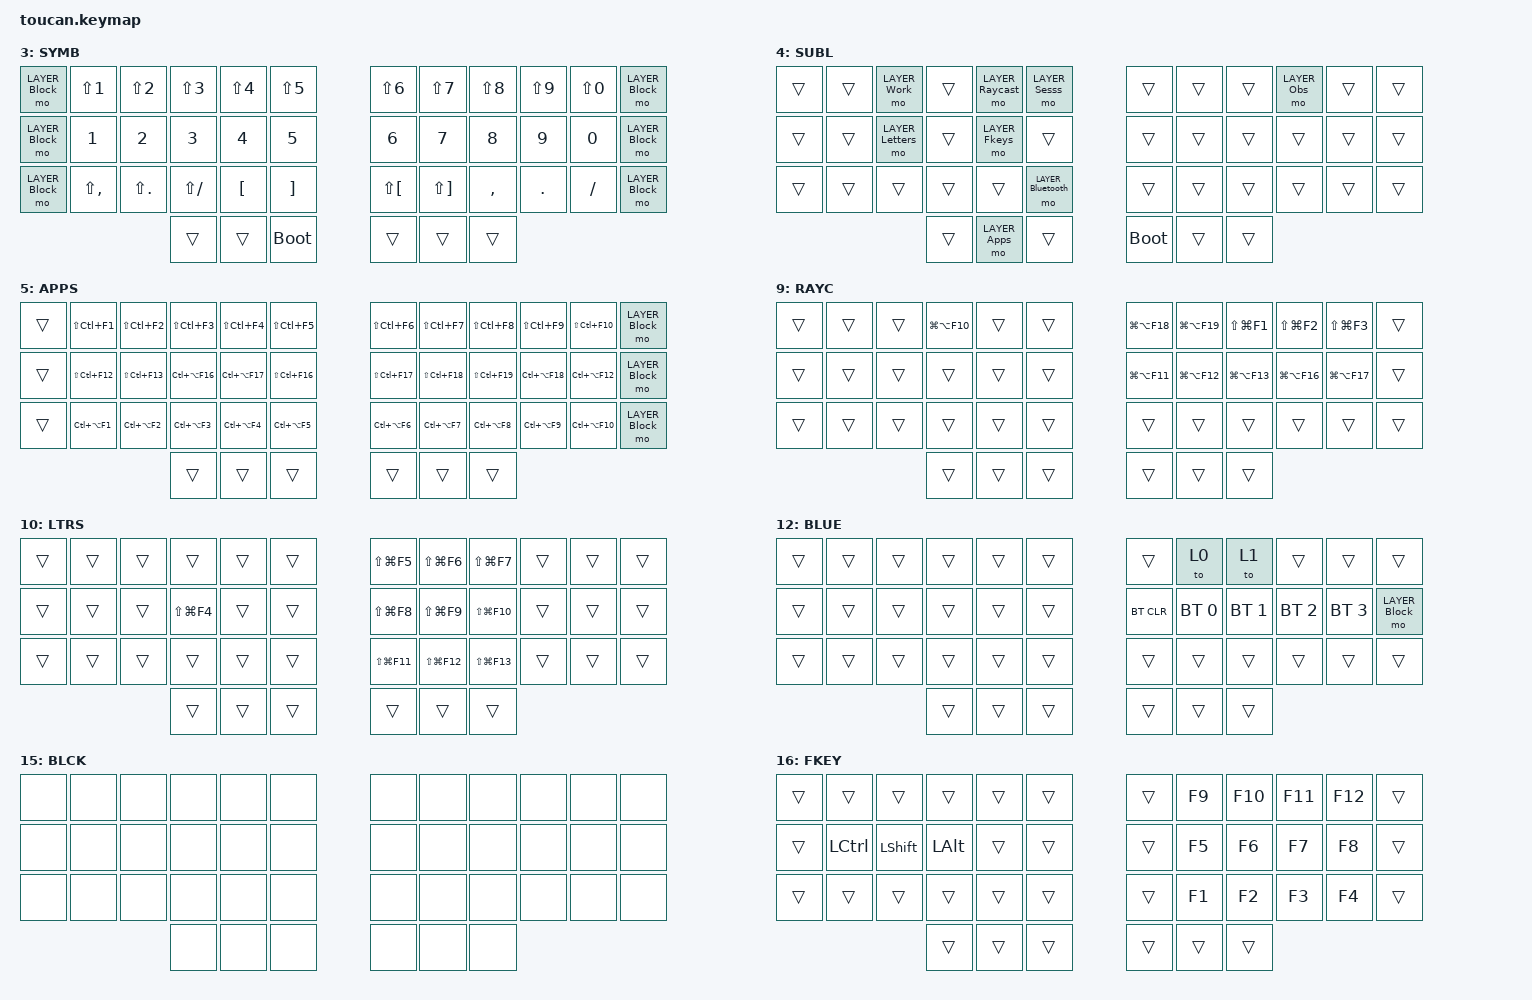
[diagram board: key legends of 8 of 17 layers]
#include <behaviors.dtsi>
#include <dt-bindings/zmk/keys.h>
#include <dt-bindings/zmk/bt.h>
#include <dt-bindings/zmk/outputs.h>

// Adding pointing.h to be able to right and middle click
// https://zmk.dev/docs/keymaps/behaviors/mouse-emulation
#include <dt-bindings/zmk/pointing.h>

#define LAYER_macOS 0
#define LAYER_Windows 1
#define LAYER_Nav 2
#define LAYER_Symb 3
#define LAYER_Subl 4
#define LAYER_Apps 5
#define LAYER_Sesss 6
#define LAYER_Systm 7
#define LAYER_Yabai 8
#define LAYER_Raycast 9
#define LAYER_Letters 10
#define LAYER_Obs 11
#define LAYER_Bluetooth 12
#define LAYER_Obspos 13
#define LAYER_Work 14
#define LAYER_Block 15
#define LAYER_Fkeys 16

/ {
    behaviors {
        // Home-row mods: a key only becomes the modifier once it has been held for tapping-term-ms.
        hrm_l: hrm_l {
            compatible = "zmk,behavior-hold-tap";
            #binding-cells = <2>;
            tapping-term-ms = <300>;
            bindings = <&kp>, <&kp>;
            flavor = "tap-preferred";
            quick-tap-ms = <300>;
        };

        hrm_r: hrm_r {
            compatible = "zmk,behavior-hold-tap";
            #binding-cells = <2>;
            tapping-term-ms = <300>;
            bindings = <&kp>, <&kp>;
            flavor = "tap-preferred";
            quick-tap-ms = <300>;
        };

        // Windows home-row mods, both hands.
        hrm_w: hrm_w {
            compatible = "zmk,behavior-hold-tap";
            #binding-cells = <2>;
            tapping-term-ms = <200>;
            bindings = <&kp>, <&kp>;
            flavor = "tap-preferred";
            quick-tap-ms = <200>;
            retro-tap;
        };

        my_mt: my_mt {
            compatible = "zmk,behavior-hold-tap";
            #binding-cells = <2>;
            flavor = "tap-preferred";
            tapping-term-ms = <300>;
            bindings = <&kp>, <&kp>;
        };

        my_lt: my_lt {
            compatible = "zmk,behavior-hold-tap";
            #binding-cells = <2>;
            flavor = "tap-preferred";
            tapping-term-ms = <300>;
            bindings = <&mo>, <&kp>;
        };

        my_mtw: my_mtw {
            compatible = "zmk,behavior-hold-tap";
            #binding-cells = <2>;
            flavor = "tap-preferred";
            tapping-term-ms = <200>;
            bindings = <&kp>, <&kp>;
        };

        h_third_app: h_third_app {
            compatible = "zmk,behavior-hold-tap";
            #binding-cells = <2>;
            flavor = "tap-preferred";
            tapping-term-ms = <300>;
            bindings = <&third_app>, <&kp>;
        };

    };

    macros {
        third_app: third_app {
            compatible = "zmk,behavior-macro";
            #binding-cells = <0>;
            wait-ms = <40>;
            tap-ms = <40>;
            bindings
                = <&macro_press &kp LGUI>
                , <&macro_tap &kp TAB &kp TAB>
                , <&macro_release &kp LGUI>
                ;
        };

    };

#define TRANSITION_COMBO_TIMEOUT_MS 35
#define TRANSITION_COMBO_PRIOR_IDLE_MS 125

    combos {
        compatible = "zmk,combos";

        combo_mac_tab_ret {
            // Both keys must be pressed within this window.
            timeout-ms = <TRANSITION_COMBO_TIMEOUT_MS>;
            // Avoids accidental combos during fast typing/rolls.
            require-prior-idle-ms = <TRANSITION_COMBO_PRIOR_IDLE_MS>;
            // Keeps hold-tap combos held until both combo keys are released.
            slow-release;
            // Physical positions for W and E.
            key-positions = <2 3>;
            // Only active on macOS, so W+E can mean something else on other layers.
            layers = <LAYER_macOS>;
            // Reuses my existing hold-tap: hold sends RET, tap sends TAB.
            bindings = <&my_mt RET TAB>;
        };

        combo_win_tab_ret {
            timeout-ms = <TRANSITION_COMBO_TIMEOUT_MS>;
            require-prior-idle-ms = <TRANSITION_COMBO_PRIOR_IDLE_MS>;
            slow-release;
            key-positions = <2 3>;
            layers = <LAYER_Windows>;
            bindings = <&my_mtw RET TAB>;
        };

        combo_sd_esc {
            timeout-ms = <TRANSITION_COMBO_TIMEOUT_MS>;
            require-prior-idle-ms = <TRANSITION_COMBO_PRIOR_IDLE_MS>;
            slow-release;
            key-positions = <14 15>;
            layers = <LAYER_macOS LAYER_Windows>;
            bindings = <&kp ESC>;
        };

        combo_df_space {
            timeout-ms = <TRANSITION_COMBO_TIMEOUT_MS>;
            require-prior-idle-ms = <TRANSITION_COMBO_PRIOR_IDLE_MS>;
            key-positions = <15 16>;
            layers = <LAYER_macOS LAYER_Windows>;
            bindings = <&kp SPACE>;
        };

        combo_er_speech {
            timeout-ms = <TRANSITION_COMBO_TIMEOUT_MS>;
            require-prior-idle-ms = <TRANSITION_COMBO_PRIOR_IDLE_MS>;
            key-positions = <3 4>;
            layers = <LAYER_macOS LAYER_Windows>;
            bindings = <&kp LG(LC(LA(LS(S))))>;
        };

        combo_bslh {
            timeout-ms = <TRANSITION_COMBO_TIMEOUT_MS>;
            require-prior-idle-ms = <TRANSITION_COMBO_PRIOR_IDLE_MS>;
            key-positions = <8 9>;
            layers = <LAYER_macOS LAYER_Windows>;
            bindings = <&kp BSLH>;
        };

        combo_sqt {
            timeout-ms = <TRANSITION_COMBO_TIMEOUT_MS>;
            require-prior-idle-ms = <TRANSITION_COMBO_PRIOR_IDLE_MS>;
            key-positions = <20 21>;
            layers = <LAYER_macOS LAYER_Windows>;
            bindings = <&kp SQT>;
        };

        combo_sym_under {
            timeout-ms = <TRANSITION_COMBO_TIMEOUT_MS>;
            require-prior-idle-ms = <TRANSITION_COMBO_PRIOR_IDLE_MS>;
            key-positions = <2 3>;
            layers = <LAYER_Symb>;
            bindings = <&kp LS(MINUS)>;
        };

        combo_sym_tilde {
            timeout-ms = <TRANSITION_COMBO_TIMEOUT_MS>;
            require-prior-idle-ms = <TRANSITION_COMBO_PRIOR_IDLE_MS>;
            key-positions = <14 15>;
            layers = <LAYER_Symb>;
            bindings = <&kp LS(GRAVE)>;
        };

        combo_sym_plus {
            timeout-ms = <TRANSITION_COMBO_TIMEOUT_MS>;
            require-prior-idle-ms = <TRANSITION_COMBO_PRIOR_IDLE_MS>;
            key-positions = <26 27>;
            layers = <LAYER_Symb>;
            bindings = <&kp LS(EQUAL)>;
        };

        combo_sym_minus {
            timeout-ms = <TRANSITION_COMBO_TIMEOUT_MS>;
            require-prior-idle-ms = <TRANSITION_COMBO_PRIOR_IDLE_MS>;
            key-positions = <8 9>;
            layers = <LAYER_Symb>;
            bindings = <&kp MINUS>;
        };

        combo_sym_grave {
            timeout-ms = <TRANSITION_COMBO_TIMEOUT_MS>;
            require-prior-idle-ms = <TRANSITION_COMBO_PRIOR_IDLE_MS>;
            key-positions = <20 21>;
            layers = <LAYER_Symb>;
            bindings = <&kp GRAVE>;
        };

        combo_sym_equal {
            timeout-ms = <TRANSITION_COMBO_TIMEOUT_MS>;
            require-prior-idle-ms = <TRANSITION_COMBO_PRIOR_IDLE_MS>;
            key-positions = <32 33>;
            layers = <LAYER_Symb>;
            bindings = <&kp EQUAL>;
        };

        combo_apps_r_top {
            timeout-ms = <TRANSITION_COMBO_TIMEOUT_MS>;
            require-prior-idle-ms = <TRANSITION_COMBO_PRIOR_IDLE_MS>;
            key-positions = <8 9>;
            layers = <LAYER_Apps>;
            bindings = <&kp LS(LC(F11))>;
        };

        combo_apps_r_home {
            timeout-ms = <TRANSITION_COMBO_TIMEOUT_MS>;
            require-prior-idle-ms = <TRANSITION_COMBO_PRIOR_IDLE_MS>;
            key-positions = <20 21>;
            layers = <LAYER_Apps>;
            bindings = <&kp LC(LA(F13))>;
        };

        combo_apps_r_bottom {
            timeout-ms = <TRANSITION_COMBO_TIMEOUT_MS>;
            require-prior-idle-ms = <TRANSITION_COMBO_PRIOR_IDLE_MS>;
            key-positions = <32 33>;
            layers = <LAYER_Apps>;
            bindings = <&kp LC(LA(F11))>;
        };

    };
};

/ {

    keymap {
        compatible = "zmk,keymap";

        layer_macOS {
            display-name = "mac";
            bindings = <
//    ┌──────────────────┬────────────────────┬────────────────────────┬──────────────────┬──────────────────────────┬─────────────────────────┐                ┌─────────────────────┬─────────────────────────┬───────────────┬────────────────────────────────────┬───────────────┬──────────────────┐
//    │ mo laltYER_Block │  &my_mt lctl(Z) Q  │ &my_lt laltYER_Systm W │ &my_mt lalt(E) E │ &my_mt lctl(lgui(f19)) R │ &my_mt lgui(lalt(f1)) T │                │          Y          │    &my_mt lgui(Z) U     │       I       │ &my_mt lgui(lctl(lalt(lsft(Z)))) O │       P       │ mo laltYER_Block │
//    ├──────────────────┼────────────────────┼────────────────────────┼──────────────────┼──────────────────────────┼─────────────────────────┤                ├─────────────────────┼─────────────────────────┼───────────────┼────────────────────────────────────┼───────────────┼──────────────────┤
//    │ mo laltYER_Block │   &hrm_l lgui A    │     &hrm_l lsft S      │  &hrm_l lalt D   │      &hrm_l lctl F       │  &my_lt laltYER_Nav G   │                │  &h_third_app 0 H   │      &hrm_r rctl J      │ &hrm_r ralt K │           &hrm_r rsft L            │ &hrm_r rgui ; │ mo laltYER_Block │
//    ├──────────────────┼────────────────────┼────────────────────────┼──────────────────┼──────────────────────────┼─────────────────────────┤                ├─────────────────────┼─────────────────────────┼───────────────┼────────────────────────────────────┼───────────────┼──────────────────┤
//    │ mo laltYER_Block │ &my_mt lgui(tab) Z │    &my_mt lgui(`) X    │ &my_mt lgui(C) C │     &my_mt lgui(V) V     │ &my_mt lgui(lalt(f8)) B │                │  &my_mt lalt(N) N   │ &my_mt lgui(lalt(f9)) M │       ,       │ &my_mt lgui(lctl(lalt(lsft(6)))) . │       /       │ mo laltYER_Block │
//    └──────────────────┴────────────────────┴────────────────────────┴──────────────────┼──────────────────────────┼─────────────────────────┼──────┐   ┌─────┼─────────────────────┼─────────────────────────┼───────────────┴────────────────────────────────────┴───────────────┴──────────────────┘
//                                                                                        │                          │  lt laltYER_Symb bspc   │ lsft │   │ spc │ lt laltYER_Subl ent │                         │
//                                                                                        └──────────────────────────┴─────────────────────────┴──────┘   └─────┴─────────────────────┴─────────────────────────┘
  &mo LAYER_Block   &my_mt LC(Z) Q     &my_lt LAYER_Systm W   &my_mt LA(E) E   &my_mt LC(LG(F19)) R   &my_mt LG(LA(F1)) T                               &kp Y                &my_mt LG(Z) U        &kp I           &my_mt LG(LC(LA(LS(Z)))) O     &kp P              &mo LAYER_Block
  &mo LAYER_Block   &hrm_l LGUI A      &hrm_l LSHFT S         &hrm_l LALT D    &hrm_l LCTRL F         &my_lt LAYER_Nav G                                &h_third_app 0 H     &hrm_r RCTRL J        &hrm_r RALT K   &hrm_r RSHFT L                 &hrm_r RGUI SEMI   &mo LAYER_Block
  &mo LAYER_Block   &my_mt LG(TAB) Z   &my_mt LG(GRAVE) X     &my_mt LG(C) C   &my_mt LG(V) V         &my_mt LG(LA(F8)) B                               &my_mt LA(N) N       &my_mt LG(LA(F9)) M   &kp COMMA       &my_mt LG(LC(LA(LS(6)))) DOT   &kp FSLH           &mo LAYER_Block
                                                                               &none                  &lt LAYER_Symb BSPC   &kp LSHFT       &kp SPACE   &lt LAYER_Subl RET   &none
            >;
        };

        layer_Windows {
            display-name = "WNDS";
            bindings = <
//    ┌──────────────────┬────────────────────────────────┬────────────────────────────────┬───────────────────┬───────────────────────────┬──────────────────────────┐                ┌─────────────────────┬──────────────────┬───────────────┬───────────────┬───────────────┬──────────────────┐
//    │ mo laltYER_Block │               Q                │       lt laltYER_Systm W       │         E         │ &my_mtw lctl(lgui(f19)) R │ &my_mtw lgui(lalt(f1)) T │                │          Y          │ &my_mt lctl(Z) U │       I       │       O       │       P       │ mo laltYER_Block │
//    ├──────────────────┼────────────────────────────────┼────────────────────────────────┼───────────────────┼───────────────────────────┼──────────────────────────┤                ├─────────────────────┼──────────────────┼───────────────┼───────────────┼───────────────┼──────────────────┤
//    │ mo laltYER_Block │         &hrm_w lalt A          │         &hrm_w lsft S          │   &hrm_w lgui D   │       &hrm_w lctl F       │     lt laltYER_Nav G     │                │          H          │  &hrm_w rctl J   │ &hrm_w rgui K │ &hrm_w rsft L │ &hrm_w ralt ; │ mo laltYER_Block │
//    ├──────────────────┼────────────────────────────────┼────────────────────────────────┼───────────────────┼───────────────────────────┼──────────────────────────┤                ├─────────────────────┼──────────────────┼───────────────┼───────────────┼───────────────┼──────────────────┤
//    │ mo laltYER_Block │ &my_mtw lsft(lalt(lgui(f6))) Z │ &my_mtw lsft(lalt(lgui(f7))) X │ &my_mtw lctl(C) C │     &my_mtw lctl(V) V     │            B             │                │          N          │        M         │       ,       │       .       │       /       │ mo laltYER_Block │
//    └──────────────────┴────────────────────────────────┴────────────────────────────────┴───────────────────┼───────────────────────────┼──────────────────────────┼──────┐   ┌─────┼─────────────────────┼──────────────────┼───────────────┴───────────────┴───────────────┴──────────────────┘
//                                                                                                             │                           │   lt laltYER_Symb bspc   │ lsft │   │ spc │ lt laltYER_Subl ent │                  │
//                                                                                                             └───────────────────────────┴──────────────────────────┴──────┘   └─────┴─────────────────────┴──────────────────┘
  &mo LAYER_Block   &kp Q                      &lt LAYER_Systm W          &kp E             &my_mtw LC(LG(F19)) R   &my_mtw LG(LA(F1)) T                               &kp Y                &my_mt LC(Z) U   &kp I           &kp O            &kp P              &mo LAYER_Block
  &mo LAYER_Block   &hrm_w LALT A              &hrm_w LSHFT S             &hrm_w LGUI D     &hrm_w LCTRL F          &lt LAYER_Nav G                                    &kp H                &hrm_w RCTRL J   &hrm_w RGUI K   &hrm_w RSHFT L   &hrm_w RALT SEMI   &mo LAYER_Block
  &mo LAYER_Block   &my_mtw LS(LA(LG(F6))) Z   &my_mtw LS(LA(LG(F7))) X   &my_mtw LC(C) C   &my_mtw LC(V) V         &kp B                                              &kp N                &kp M            &kp COMMA       &kp DOT          &kp FSLH           &mo LAYER_Block
                                                                                            &none                   &lt LAYER_Symb BSPC    &kp LSHFT       &kp SPACE   &lt LAYER_Subl RET   &none
            >;
        };


        layer_Nav {
                  display-name = "NAVI";
            bindings = <
//    ┌──────────────────┬───────────────────────────┬───────────────────────────┬───────────────────────────┬───────────────────────────┬──────┐                                        ┌──────┬──────┬──────┬──────┬───────────────────────────┬─────┐
//    │ mo laltYER_Block │ lgui(lctl(lalt(lsft(D)))) │ lgui(lctl(lalt(lsft(0)))) │          lgui([)          │          lgui(])          │      │                                        │ home │ pgdn │ pgup │ end  │                           │     │
//    ├──────────────────┼───────────────────────────┼───────────────────────────┼───────────────────────────┼───────────────────────────┼──────┤                                        ├──────┼──────┼──────┼──────┼───────────────────────────┼─────┤
//    │                  │ lgui(lctl(lalt(lsft(G)))) │ lgui(lctl(lalt(lsft(=)))) │ lgui(lctl(lalt(lsft(9)))) │ lgui(lctl(lalt(lsft(W)))) │      │                                        │ left │ down │  up  │ rght │ lgui(lctl(lalt(lsft(;)))) │     │
//    ├──────────────────┼───────────────────────────┼───────────────────────────┼───────────────────────────┼───────────────────────────┼──────┤                                        ├──────┼──────┼──────┼──────┼───────────────────────────┼─────┤
//    │                  │                           │                           │                           │ lgui(lctl(lalt(lsft(B)))) │      │                                        │      │      │      │      │                           │     │
//    └──────────────────┴───────────────────────────┴───────────────────────────┴───────────────────────────┼───────────────────────────┼──────┼──────┐   ┌─────────────────────────────┼──────┼──────┼──────┴──────┴───────────────────────────┴─────┘
//                                                                                                           │                           │ rclk │ mclk │   │ lgui(lctl(lalt(lsft(tab)))) │ caps │      │
//                                                                                                           └───────────────────────────┴──────┴──────┘   └─────────────────────────────┴──────┴──────┘
  &mo LAYER_Block   &kp LG(LC(LA(LS(D))))   &kp LG(LC(LA(LS(N0))))      &kp LG(LBKT)             &kp LG(RBKT)            &trans                                                &kp HOME       &kp PG_DN   &kp PG_UP   &kp END     &trans                     &trans
  &trans            &kp LG(LC(LA(LS(G))))   &kp LG(LC(LA(LS(EQUAL))))   &kp LG(LC(LA(LS(N9))))   &kp LG(LC(LA(LS(W))))   &trans                                                &kp LEFT       &kp DOWN    &kp UP      &kp RIGHT   &kp LG(LC(LA(LS(SEMI))))   &trans
  &trans            &trans                  &trans                      &trans                   &kp LG(LC(LA(LS(B))))   &trans                                                &trans         &trans      &trans      &trans      &trans                     &trans
                                                                                                 &trans                  &mkp RCLK   &mkp MCLK       &kp LG(LC(LA(LS(TAB))))   &kp CAPSLOCK   &trans
            >;
        };

        layer_Symb {
            display-name = "SYMB";
            bindings = <
//    ┌──────────────────┬─────────┬─────────┬─────────┬─────────┬─────────┐                ┌─────────┬─────────┬─────────┬─────────┬─────────┬──────────────────┐
//    │ mo laltYER_Block │ lsft(1) │ lsft(2) │ lsft(3) │ lsft(4) │ lsft(5) │                │ lsft(6) │ lsft(7) │ lsft(8) │ lsft(9) │ lsft(0) │ mo laltYER_Block │
//    ├──────────────────┼─────────┼─────────┼─────────┼─────────┼─────────┤                ├─────────┼─────────┼─────────┼─────────┼─────────┼──────────────────┤
//    │ mo laltYER_Block │    1    │    2    │    3    │    4    │    5    │                │    6    │    7    │    8    │    9    │    0    │ mo laltYER_Block │
//    ├──────────────────┼─────────┼─────────┼─────────┼─────────┼─────────┤                ├─────────┼─────────┼─────────┼─────────┼─────────┼──────────────────┤
//    │ mo laltYER_Block │ lsft(,) │ lsft(.) │ lsft(/) │    [    │    ]    │                │ lsft([) │ lsft(]) │    ,    │    .    │    /    │ mo laltYER_Block │
//    └──────────────────┴─────────┴─────────┴─────────┼─────────┼─────────┼──────┐   ┌─────┼─────────┼─────────┼─────────┴─────────┴─────────┴──────────────────┘
//                                                     │         │         │ boot │   │     │         │         │
//                                                     └─────────┴─────────┴──────┘   └─────┴─────────┴─────────┘
  &mo LAYER_Block   &kp LS(N1)      &kp LS(N2)    &kp LS(N3)     &kp LS(N4)   &kp LS(N5)                              &kp LS(N6)     &kp LS(N7)     &kp LS(N8)   &kp LS(N9)   &kp LS(N0)   &mo LAYER_Block
  &mo LAYER_Block   &kp N1          &kp N2        &kp N3         &kp N4       &kp N5                                  &kp N6         &kp N7         &kp N8       &kp N9       &kp N0       &mo LAYER_Block
  &mo LAYER_Block   &kp LS(COMMA)   &kp LS(DOT)   &kp LS(FSLH)   &kp LBKT     &kp RBKT                                &kp LS(LBKT)   &kp LS(RBKT)   &kp COMMA    &kp DOT      &kp FSLH     &mo LAYER_Block
                                                                 &trans       &trans       &bootloader       &trans   &trans         &trans
            >;
        };


        layer_Subl {
            display-name = "SUBL";
            bindings = <
//    ┌─────┬─────┬────────────────────┬─────┬────────────────────┬──────────────────────┐                ┌─────┬─────┬─────┬────────────────┬─────┬─────┐
//    │     │     │  mo laltYER_Work   │     │ mo laltYER_Raycast │   mo laltYER_Sesss   │                │     │     │     │ mo laltYER_Obs │     │     │
//    ├─────┼─────┼────────────────────┼─────┼────────────────────┼──────────────────────┤                ├─────┼─────┼─────┼────────────────┼─────┼─────┤
//    │     │     │ mo laltYER_Letters │     │  mo laltYER_Fkeys  │                      │                │     │     │     │                │     │     │
//    ├─────┼─────┼────────────────────┼─────┼────────────────────┼──────────────────────┤                ├─────┼─────┼─────┼────────────────┼─────┼─────┤
//    │     │     │                    │     │                    │ mo laltYER_Bluetooth │                │     │     │     │                │     │     │
//    └─────┴─────┴────────────────────┴─────┼────────────────────┼──────────────────────┼─────┐   ┌──────┼─────┼─────┼─────┴────────────────┴─────┴─────┘
//                                           │                    │   mo laltYER_Apps    │     │   │ boot │     │     │
//                                           └────────────────────┴──────────────────────┴─────┘   └──────┴─────┴─────┘
  &trans   &trans   &mo LAYER_Work      &trans   &mo LAYER_Raycast   &mo LAYER_Sesss                                  &trans   &trans   &trans   &mo LAYER_Obs   &trans   &trans
  &trans   &trans   &mo LAYER_Letters   &trans   &mo LAYER_Fkeys     &trans                                           &trans   &trans   &trans   &trans          &trans   &trans
  &trans   &trans   &trans              &trans   &trans              &mo LAYER_Bluetooth                              &trans   &trans   &trans   &trans          &trans   &trans
                                                 &trans              &mo LAYER_Apps        &trans       &bootloader   &trans   &trans
            >;
        };

          layer_Apps {
            display-name = "APPS";
            bindings = <
//    ┌─────┬─────────────────┬─────────────────┬─────────────────┬─────────────────┬─────────────────┐               ┌─────────────────┬─────────────────┬─────────────────┬─────────────────┬─────────────────┬──────────────────┐
//    │     │ lsft(lctl(f1))  │ lsft(lctl(f2))  │ lsft(lctl(f3))  │ lsft(lctl(f4))  │ lsft(lctl(f5))  │               │ lsft(lctl(f6))  │ lsft(lctl(f7))  │ lsft(lctl(f8))  │ lsft(lctl(f9))  │ lsft(lctl(f10)) │ mo laltYER_Block │
//    ├─────┼─────────────────┼─────────────────┼─────────────────┼─────────────────┼─────────────────┤               ├─────────────────┼─────────────────┼─────────────────┼─────────────────┼─────────────────┼──────────────────┤
//    │     │ lsft(lctl(f12)) │ lsft(lctl(f13)) │ lctl(lalt(f16)) │ lctl(lalt(f17)) │ lsft(lctl(f16)) │               │ lsft(lctl(f17)) │ lsft(lctl(f18)) │ lsft(lctl(f19)) │ lctl(lalt(f18)) │ lctl(lalt(f12)) │ mo laltYER_Block │
//    ├─────┼─────────────────┼─────────────────┼─────────────────┼─────────────────┼─────────────────┤               ├─────────────────┼─────────────────┼─────────────────┼─────────────────┼─────────────────┼──────────────────┤
//    │     │ lctl(lalt(f1))  │ lctl(lalt(f2))  │ lctl(lalt(f3))  │ lctl(lalt(f4))  │ lctl(lalt(f5))  │               │ lctl(lalt(f6))  │ lctl(lalt(f7))  │ lctl(lalt(f8))  │ lctl(lalt(f9))  │ lctl(lalt(f10)) │ mo laltYER_Block │
//    └─────┴─────────────────┴─────────────────┴─────────────────┼─────────────────┼─────────────────┼─────┐   ┌─────┼─────────────────┼─────────────────┼─────────────────┴─────────────────┴─────────────────┴──────────────────┘
//                                                                │                 │                 │     │   │     │                 │                 │
//                                                                └─────────────────┴─────────────────┴─────┘   └─────┴─────────────────┴─────────────────┘
  &trans   &kp LS(LC(F1))    &kp LS(LC(F2))    &kp LS(LC(F3))    &kp LS(LC(F4))    &kp LS(LC(F5))                          &kp LS(LC(F6))    &kp LS(LC(F7))    &kp LS(LC(F8))    &kp LS(LC(F9))    &kp LS(LC(F10))   &mo LAYER_Block
  &trans   &kp LS(LC(F12))   &kp LS(LC(F13))   &kp LC(LA(F16))   &kp LC(LA(F17))   &kp LS(LC(F16))                         &kp LS(LC(F17))   &kp LS(LC(F18))   &kp LS(LC(F19))   &kp LC(LA(F18))   &kp LC(LA(F12))   &mo LAYER_Block
  &trans   &kp LC(LA(F1))    &kp LC(LA(F2))    &kp LC(LA(F3))    &kp LC(LA(F4))    &kp LC(LA(F5))                          &kp LC(LA(F6))    &kp LC(LA(F7))    &kp LC(LA(F8))    &kp LC(LA(F9))    &kp LC(LA(F10))   &mo LAYER_Block
                                                                 &trans            &trans            &trans       &trans   &trans            &trans
            >;
        };

          layer_Sess {
            display-name = "SESS";
            bindings = <
//    ┌─────┬─────┬───────────────────────┬─────────────────┬─────────────────┬─────┐               ┌─────────────────┬─────────────────┬─────────────────┬─────────────────┬─────────────────┬─────┐
//    │     │     │ lsft(lalt(lgui(f10))) │ lctl(lgui(f12)) │ lctl(lgui(f13)) │     │               │ lctl(lgui(f16)) │ lctl(lgui(f17)) │ lctl(lgui(f18)) │ lctl(lalt(f19)) │ lctl(lgui(f1))  │     │
//    ├─────┼─────┼───────────────────────┼─────────────────┼─────────────────┼─────┤               ├─────────────────┼─────────────────┼─────────────────┼─────────────────┼─────────────────┼─────┤
//    │     │     │                       │                 │                 │     │               │ lctl(lgui(f2))  │ lctl(lgui(f3))  │ lctl(lgui(f4))  │ lctl(lgui(f5))  │ lctl(lgui(f6))  │     │
//    ├─────┼─────┼───────────────────────┼─────────────────┼─────────────────┼─────┤               ├─────────────────┼─────────────────┼─────────────────┼─────────────────┼─────────────────┼─────┤
//    │     │     │                       │                 │                 │     │               │ lctl(lgui(f7))  │ lctl(lgui(f8))  │ lctl(lgui(f9))  │ lctl(lgui(f10)) │ lctl(lgui(f11)) │     │
//    └─────┴─────┴───────────────────────┴─────────────────┼─────────────────┼─────┼─────┐   ┌─────┼─────────────────┼─────────────────┼─────────────────┴─────────────────┴─────────────────┴─────┘
//                                                          │                 │     │     │   │     │                 │                 │
//                                                          └─────────────────┴─────┴─────┘   └─────┴─────────────────┴─────────────────┘
  &trans   &trans   &kp LS(LA(LG(F10)))   &kp LC(LG(F12))   &kp LC(LG(F13))   &trans                         &kp LC(LG(F16))   &kp LC(LG(F17))   &kp LC(LG(F18))   &kp LC(LA(F19))   &kp LC(LG(F1))    &trans
  &trans   &trans   &trans                &trans            &trans            &trans                         &kp LC(LG(F2))    &kp LC(LG(F3))    &kp LC(LG(F4))    &kp LC(LG(F5))    &kp LC(LG(F6))    &trans
  &trans   &trans   &trans                &trans            &trans            &trans                         &kp LC(LG(F7))    &kp LC(LG(F8))    &kp LC(LG(F9))    &kp LC(LG(F10))   &kp LC(LG(F11))   &trans
                                                            &trans            &trans   &trans       &trans   &trans            &trans
            >;
        };


              layer_Systm {
            display-name = "SYST";
            bindings = <
//    ┌──────────────────┬────────────────┬─────┬──────┬──────────────────────────┬───────────────────────┐                                ┌────────────────┬────────────────┬──────┬───────────────┬──────┬─────┐
//    │                  │ lgui(lalt(f2)) │     │ volu │ lt laltYER_Yabai lgui(=) │    lgui(lalt(f3))     │                                │      prev      │      bri-      │ bri+ │     next      │ play │     │
//    ├──────────────────┼────────────────┼─────┼──────┼──────────────────────────┼───────────────────────┤                                ├────────────────┼────────────────┼──────┼───────────────┼──────┼─────┤
//    │ mo laltYER_Block │ lgui(lctl(Q))  │     │ vold │         lgui(-)          │    lgui(lalt(f4))     │                                │ lgui(lsft([))  │ lgui(lalt(f6)) │      │ lgui(lsft(])) │      │     │
//    ├──────────────────┼────────────────┼─────┼──────┼──────────────────────────┼───────────────────────┤                                ├────────────────┼────────────────┼──────┼───────────────┼──────┼─────┤
//    │                  │                │     │      │                          │ lsft(lalt(lgui(f19))) │                                │ lgui(lalt(f5)) │ lgui(lalt(f7)) │      │               │      │     │
//    └──────────────────┴────────────────┴─────┴──────┼──────────────────────────┼───────────────────────┼──────────────────────┐   ┌─────┼────────────────┼────────────────┼──────┴───────────────┴──────┴─────┘
//                                                     │                          │        lgui(W)        │ lctl(lalt(lgui(f1))) │   │     │                │                │
//                                                     └──────────────────────────┴───────────────────────┴──────────────────────┘   └─────┴────────────────┴────────────────┘
  &trans            &kp LG(LA(F2))   &trans   &kp K_VOL_UP   &lt LAYER_Yabai LG(EQUAL)   &kp LG(LA(F3))                                          &kp C_PREV         &kp C_BRI_DN     &kp C_BRI_UP   &kp C_NEXT         &kp C_PP   &trans
  &mo LAYER_Block   &kp LG(LC(Q))    &trans   &kp K_VOL_DN   &kp LG(MINUS)               &kp LG(LA(F4))                                          &kp LG(LS(LBKT))   &kp LG(LA(F6))   &trans         &kp LG(LS(RBKT))   &trans     &trans
  &trans            &trans           &trans   &trans         &trans                      &kp LS(LA(LG(F19)))                                     &kp LG(LA(F5))     &kp LG(LA(F7))   &trans         &trans             &trans     &trans
                                                             &trans                      &kp LG(W)             &kp LC(LA(LG(F1)))       &trans   &trans             &trans
            >;
        };

              layer_Yabai {
            display-name = "YABA";
            bindings = <
//    ┌─────┬─────┬─────┬─────┬───────────────────────┬─────┐               ┌───────────────────────┬───────────────────────┬───────────────────────┬───────────────────────┬─────┬─────┐
//    │     │     │     │     │ lsft(lalt(lctl(f10))) │     │               │ lsft(lalt(lctl(f11))) │ lsft(lalt(lctl(f12))) │ lsft(lalt(lctl(f13))) │ lsft(lalt(lctl(f16))) │     │     │
//    ├─────┼─────┼─────┼─────┼───────────────────────┼─────┤               ├───────────────────────┼───────────────────────┼───────────────────────┼───────────────────────┼─────┼─────┤
//    │     │     │     │     │                       │     │               │ lsft(lalt(lctl(f17))) │ lsft(lalt(lctl(f18))) │ lsft(lalt(lctl(f19))) │ lsft(lalt(lgui(f1)))  │     │     │
//    ├─────┼─────┼─────┼─────┼───────────────────────┼─────┤               ├───────────────────────┼───────────────────────┼───────────────────────┼───────────────────────┼─────┼─────┤
//    │     │     │     │     │                       │     │               │ lsft(lalt(lgui(f2)))  │ lsft(lalt(lgui(f3)))  │ lsft(lalt(lgui(f4)))  │ lsft(lalt(lgui(f5)))  │     │     │
//    └─────┴─────┴─────┴─────┼───────────────────────┼─────┼─────┐   ┌─────┼───────────────────────┼───────────────────────┼───────────────────────┴───────────────────────┴─────┴─────┘
//                            │                       │     │     │   │     │                       │                       │
//                            └───────────────────────┴─────┴─────┘   └─────┴───────────────────────┴───────────────────────┘
  &trans   &trans   &trans   &trans   &kp LS(LA(LC(F10)))   &trans                         &kp LS(LA(LC(F11)))   &kp LS(LA(LC(F12)))   &kp LS(LA(LC(F13)))   &kp LS(LA(LC(F16)))   &trans   &trans
  &trans   &trans   &trans   &trans   &trans                &trans                         &kp LS(LA(LC(F17)))   &kp LS(LA(LC(F18)))   &kp LS(LA(LC(F19)))   &kp LS(LA(LG(F1)))    &trans   &trans
  &trans   &trans   &trans   &trans   &trans                &trans                         &kp LS(LA(LG(F2)))    &kp LS(LA(LG(F3)))    &kp LS(LA(LG(F4)))    &kp LS(LA(LG(F5)))    &trans   &trans
                                      &trans                &trans   &trans       &trans   &trans                &trans
            >;
        };

       
              layer_Raycast {
            display-name = "RAYC";
            bindings = <
//    ┌─────┬─────┬─────┬─────────────────┬─────┬─────┐               ┌─────────────────┬─────────────────┬─────────────────┬─────────────────┬─────────────────┬─────┐
//    │     │     │     │ lgui(lalt(f10)) │     │     │               │ lgui(lalt(f18)) │ lgui(lalt(f19)) │ lsft(lgui(f1))  │ lsft(lgui(f2))  │ lsft(lgui(f3))  │     │
//    ├─────┼─────┼─────┼─────────────────┼─────┼─────┤               ├─────────────────┼─────────────────┼─────────────────┼─────────────────┼─────────────────┼─────┤
//    │     │     │     │                 │     │     │               │ lgui(lalt(f11)) │ lgui(lalt(f12)) │ lgui(lalt(f13)) │ lgui(lalt(f16)) │ lgui(lalt(f17)) │     │
//    ├─────┼─────┼─────┼─────────────────┼─────┼─────┤               ├─────────────────┼─────────────────┼─────────────────┼─────────────────┼─────────────────┼─────┤
//    │     │     │     │                 │     │     │               │                 │                 │                 │                 │                 │     │
//    └─────┴─────┴─────┴─────────────────┼─────┼─────┼─────┐   ┌─────┼─────────────────┼─────────────────┼─────────────────┴─────────────────┴─────────────────┴─────┘
//                                        │     │     │     │   │     │                 │                 │
//                                        └─────┴─────┴─────┘   └─────┴─────────────────┴─────────────────┘
  &trans   &trans   &trans   &kp LG(LA(F10))   &trans   &trans                         &kp LG(LA(F18))   &kp LG(LA(F19))   &kp LS(LG(F1))    &kp LS(LG(F2))    &kp LS(LG(F3))    &trans
  &trans   &trans   &trans   &trans            &trans   &trans                         &kp LG(LA(F11))   &kp LG(LA(F12))   &kp LG(LA(F13))   &kp LG(LA(F16))   &kp LG(LA(F17))   &trans
  &trans   &trans   &trans   &trans            &trans   &trans                         &trans            &trans            &trans            &trans            &trans            &trans
                                               &trans   &trans   &trans       &trans   &trans            &trans
            >;
        };


              layer_Letters {
            display-name = "LTRS";
            bindings = <
//    ┌─────┬─────┬─────┬────────────────┬─────┬─────┐               ┌─────────────────┬─────────────────┬─────────────────┬─────┬─────┬─────┐
//    │     │     │     │                │     │     │               │ lsft(lgui(f5))  │ lsft(lgui(f6))  │ lsft(lgui(f7))  │     │     │     │
//    ├─────┼─────┼─────┼────────────────┼─────┼─────┤               ├─────────────────┼─────────────────┼─────────────────┼─────┼─────┼─────┤
//    │     │     │     │ lsft(lgui(f4)) │     │     │               │ lsft(lgui(f8))  │ lsft(lgui(f9))  │ lsft(lgui(f10)) │     │     │     │
//    ├─────┼─────┼─────┼────────────────┼─────┼─────┤               ├─────────────────┼─────────────────┼─────────────────┼─────┼─────┼─────┤
//    │     │     │     │                │     │     │               │ lsft(lgui(f11)) │ lsft(lgui(f12)) │ lsft(lgui(f13)) │     │     │     │
//    └─────┴─────┴─────┴────────────────┼─────┼─────┼─────┐   ┌─────┼─────────────────┼─────────────────┼─────────────────┴─────┴─────┴─────┘
//                                       │     │     │     │   │     │                 │                 │
//                                       └─────┴─────┴─────┘   └─────┴─────────────────┴─────────────────┘
  &trans   &trans   &trans   &trans           &trans   &trans                         &kp LS(LG(F5))    &kp LS(LG(F6))    &kp LS(LG(F7))    &trans   &trans   &trans
  &trans   &trans   &trans   &kp LS(LG(F4))   &trans   &trans                         &kp LS(LG(F8))    &kp LS(LG(F9))    &kp LS(LG(F10))   &trans   &trans   &trans
  &trans   &trans   &trans   &trans           &trans   &trans                         &kp LS(LG(F11))   &kp LS(LG(F12))   &kp LS(LG(F13))   &trans   &trans   &trans
                                              &trans   &trans   &trans       &trans   &trans            &trans
            >;
        };

        // Test comment
        layer_Obs {
            display-name = "OBS";
            bindings = <
//    ┌─────┬─────────────────┬──────────────────────┬──────────────────────┬──────────────────────┬──────────────────────┐               ┌──────────────────────┬──────────────────────┬──────────────────────┬──────────────────────┬──────────────────────┬─────┐
//    │     │ lsft(lalt(f1))  │    lsft(lalt(f2))    │    lsft(lalt(f3))    │    lsft(lalt(f4))    │    lsft(lalt(f5))    │               │    lsft(lalt(f6))    │    lsft(lalt(f7))    │    lsft(lalt(f8))    │                      │  mo laltYER_Obspos   │     │
//    ├─────┼─────────────────┼──────────────────────┼──────────────────────┼──────────────────────┼──────────────────────┤               ├──────────────────────┼──────────────────────┼──────────────────────┼──────────────────────┼──────────────────────┼─────┤
//    │     │ lsft(lalt(f11)) │   lsft(lalt(f12))    │   lsft(lalt(f13))    │   lsft(lalt(f16))    │   lsft(lalt(f17))    │               │   lsft(lalt(f18))    │   lsft(lalt(f19))    │   lsft(lgui(f16))    │   lsft(lgui(f17))    │   lsft(lgui(f18))    │     │
//    ├─────┼─────────────────┼──────────────────────┼──────────────────────┼──────────────────────┼──────────────────────┤               ├──────────────────────┼──────────────────────┼──────────────────────┼──────────────────────┼──────────────────────┼─────┤
//    │     │ lsft(lgui(f19)) │ lsft(lalt(lctl(f1))) │ lsft(lalt(lctl(f2))) │ lsft(lalt(lctl(f3))) │ lsft(lalt(lctl(f4))) │               │ lsft(lalt(lctl(f5))) │ lsft(lalt(lctl(f6))) │ lsft(lalt(lctl(f7))) │ lsft(lalt(lctl(f8))) │ lsft(lalt(lctl(f9))) │     │
//    └─────┴─────────────────┴──────────────────────┴──────────────────────┼──────────────────────┼──────────────────────┼─────┐   ┌─────┼──────────────────────┼──────────────────────┼──────────────────────┴──────────────────────┴──────────────────────┴─────┘
//                                                                          │                      │                      │     │   │     │                      │                      │
//                                                                          └──────────────────────┴──────────────────────┴─────┘   └─────┴──────────────────────┴──────────────────────┘
  &trans   &kp LS(LA(F1))    &kp LS(LA(F2))       &kp LS(LA(F3))       &kp LS(LA(F4))       &kp LS(LA(F5))                             &kp LS(LA(F6))       &kp LS(LA(F7))       &kp LS(LA(F8))       &trans               &mo LAYER_Obspos     &trans
  &trans   &kp LS(LA(F11))   &kp LS(LA(F12))      &kp LS(LA(F13))      &kp LS(LA(F16))      &kp LS(LA(F17))                            &kp LS(LA(F18))      &kp LS(LA(F19))      &kp LS(LG(F16))      &kp LS(LG(F17))      &kp LS(LG(F18))      &trans
  &trans   &kp LS(LG(F19))   &kp LS(LA(LC(F1)))   &kp LS(LA(LC(F2)))   &kp LS(LA(LC(F3)))   &kp LS(LA(LC(F4)))                         &kp LS(LA(LC(F5)))   &kp LS(LA(LC(F6)))   &kp LS(LA(LC(F7)))   &kp LS(LA(LC(F8)))   &kp LS(LA(LC(F9)))   &trans
                                                                       &trans               &trans               &trans       &trans   &trans               &trans
            >;
        };


          layer_Bluetooth {
            display-name = "BLUE";
            bindings = <
//    ┌─────┬─────┬─────┬─────┬─────┬─────┐               ┌────────┬──────────┬──────────┬──────────┬──────────┬──────────────────┐
//    │     │     │     │     │     │     │               │        │   to 0   │   to 1   │          │          │                  │
//    ├─────┼─────┼─────┼─────┼─────┼─────┤               ├────────┼──────────┼──────────┼──────────┼──────────┼──────────────────┤
//    │     │     │     │     │     │     │               │ bt_clr │ bt_sel 0 │ bt_sel 1 │ bt_sel 2 │ bt_sel 3 │ mo laltYER_Block │
//    ├─────┼─────┼─────┼─────┼─────┼─────┤               ├────────┼──────────┼──────────┼──────────┼──────────┼──────────────────┤
//    │     │     │     │     │     │     │               │        │          │          │          │          │                  │
//    └─────┴─────┴─────┴─────┼─────┼─────┼─────┐   ┌─────┼────────┼──────────┼──────────┴──────────┴──────────┴──────────────────┘
//                            │     │     │     │   │     │        │          │
//                            └─────┴─────┴─────┘   └─────┴────────┴──────────┘
  &trans   &trans   &trans   &trans   &trans   &trans                         &trans       &to 0          &to 1          &trans         &trans         &trans
  &trans   &trans   &trans   &trans   &trans   &trans                         &bt BT_CLR   &bt BT_SEL 0   &bt BT_SEL 1   &bt BT_SEL 2   &bt BT_SEL 3   &mo LAYER_Block
  &trans   &trans   &trans   &trans   &trans   &trans                         &trans       &trans         &trans         &trans         &trans         &trans
                                      &trans   &trans   &trans       &trans   &trans       &trans
            >;
        };

      
        layer_Obspos {
            display-name = "OBP";
            bindings = <
//    ┌─────┬────────────────┬─────────────────┬──────────────────────┬──────────────────────┬─────┐               ┌─────┬─────┬─────┬─────┬─────┬─────┐
//    │     │                │                 │                      │                      │     │               │     │     │     │     │     │     │
//    ├─────┼────────────────┼─────────────────┼──────────────────────┼──────────────────────┼─────┤               ├─────┼─────┼─────┼─────┼─────┼─────┤
//    │     │ lsft(lalt(f9)) │ lsft(lalt(f10)) │ lsft(lalt(lgui(f8))) │ lsft(lalt(lgui(f9))) │     │               │     │     │     │     │     │     │
//    ├─────┼────────────────┼─────────────────┼──────────────────────┼──────────────────────┼─────┤               ├─────┼─────┼─────┼─────┼─────┼─────┤
//    │     │                │                 │                      │                      │     │               │     │     │     │     │     │     │
//    └─────┴────────────────┴─────────────────┴──────────────────────┼──────────────────────┼─────┼─────┐   ┌─────┼─────┼─────┼─────┴─────┴─────┴─────┘
//                                                                    │                      │     │     │   │     │     │     │
//                                                                    └──────────────────────┴─────┴─────┘   └─────┴─────┴─────┘
  &trans   &trans           &trans            &trans               &trans               &trans                         &trans   &trans   &trans   &trans   &trans   &trans
  &trans   &kp LS(LA(F9))   &kp LS(LA(F10))   &kp LS(LA(LG(F8)))   &kp LS(LA(LG(F9)))   &trans                         &trans   &trans   &trans   &trans   &trans   &trans
  &trans   &trans           &trans            &trans               &trans               &trans                         &trans   &trans   &trans   &trans   &trans   &trans
                                                                   &trans               &trans   &trans       &trans   &trans   &trans
            >;
        };


        layer_Work {
            display-name = "WRK";
            bindings = <
//    ┌─────┬─────┬─────┬─────┬───────────────────────┬─────┐               ┌─────┬───────────────────────┬───────────────────────┬───────────────────────┬───────────────────────┬─────┐
//    │     │     │     │     │                       │     │               │     │                       │                       │ lsft(lalt(lgui(f12))) │                       │     │
//    ├─────┼─────┼─────┼─────┼───────────────────────┼─────┤               ├─────┼───────────────────────┼───────────────────────┼───────────────────────┼───────────────────────┼─────┤
//    │     │     │     │     │ lsft(lalt(lgui(f18))) │     │               │     │ lsft(lalt(lgui(f16))) │ lsft(lalt(lgui(f11))) │                       │ lsft(lalt(lgui(f17))) │     │
//    ├─────┼─────┼─────┼─────┼───────────────────────┼─────┤               ├─────┼───────────────────────┼───────────────────────┼───────────────────────┼───────────────────────┼─────┤
//    │     │     │     │     │                       │     │               │     │ lsft(lalt(lgui(f13))) │                       │                       │                       │     │
//    └─────┴─────┴─────┴─────┼───────────────────────┼─────┼─────┐   ┌─────┼─────┼───────────────────────┼───────────────────────┴───────────────────────┴───────────────────────┴─────┘
//                            │                       │     │     │   │     │     │                       │
//                            └───────────────────────┴─────┴─────┘   └─────┴─────┴───────────────────────┘
  &trans   &trans   &trans   &trans   &trans                &trans                         &trans   &trans                &trans                &kp LS(LA(LG(F12)))   &trans                &trans
  &trans   &trans   &trans   &trans   &kp LS(LA(LG(F18)))   &trans                         &trans   &kp LS(LA(LG(F16)))   &kp LS(LA(LG(F11)))   &trans                &kp LS(LA(LG(F17)))   &trans
  &trans   &trans   &trans   &trans   &trans                &trans                         &trans   &kp LS(LA(LG(F13)))   &trans                &trans                &trans                &trans
                                      &trans                &trans   &trans       &trans   &trans   &trans
            >;
        };


        // Physical shift keys hold this highest layer to swallow accidental chords.
        // This is while I get used to shift in homerow mods
        layer_Block {
            display-name = "BLCK";
            bindings = <
//    ┌─────┬─────┬─────┬─────┬─────┬─────┐               ┌─────┬─────┬─────┬─────┬─────┬─────┐
//    │     │     │     │     │     │     │               │     │     │     │     │     │     │
//    ├─────┼─────┼─────┼─────┼─────┼─────┤               ├─────┼─────┼─────┼─────┼─────┼─────┤
//    │     │     │     │     │     │     │               │     │     │     │     │     │     │
//    ├─────┼─────┼─────┼─────┼─────┼─────┤               ├─────┼─────┼─────┼─────┼─────┼─────┤
//    │     │     │     │     │     │     │               │     │     │     │     │     │     │
//    └─────┴─────┴─────┴─────┼─────┼─────┼─────┐   ┌─────┼─────┼─────┼─────┴─────┴─────┴─────┘
//                            │     │     │     │   │     │     │     │
//                            └─────┴─────┴─────┘   └─────┴─────┴─────┘
  &none   &none   &none   &none   &none   &none                       &none   &none   &none   &none   &none   &none
  &none   &none   &none   &none   &none   &none                       &none   &none   &none   &none   &none   &none
  &none   &none   &none   &none   &none   &none                       &none   &none   &none   &none   &none   &none
                                  &none   &none   &none       &none   &none   &none
            >;
        };

        layer_Fkeys {
            display-name = "FKEY";
            bindings = <
//    ┌─────┬──────┬──────┬──────┬─────┬─────┐               ┌─────┬─────┬─────┬─────┬─────┬─────┐
//    │     │      │      │      │     │     │               │     │ f9  │ f10 │ f11 │ f12 │     │
//    ├─────┼──────┼──────┼──────┼─────┼─────┤               ├─────┼─────┼─────┼─────┼─────┼─────┤
//    │     │ lctl │ lsft │ lalt │     │     │               │     │ f5  │ f6  │ f7  │ f8  │     │
//    ├─────┼──────┼──────┼──────┼─────┼─────┤               ├─────┼─────┼─────┼─────┼─────┼─────┤
//    │     │      │      │      │     │     │               │     │ f1  │ f2  │ f3  │ f4  │     │
//    └─────┴──────┴──────┴──────┼─────┼─────┼─────┐   ┌─────┼─────┼─────┼─────┴─────┴─────┴─────┘
//                               │     │     │     │   │     │     │     │
//                               └─────┴─────┴─────┘   └─────┴─────┴─────┘
  &trans   &trans      &trans      &trans     &trans   &trans                         &trans   &kp F9   &kp F10   &kp F11   &kp F12   &trans
  &trans   &kp LCTRL   &kp LSHFT   &kp LALT   &trans   &trans                         &trans   &kp F5   &kp F6    &kp F7    &kp F8    &trans
  &trans   &trans      &trans      &trans     &trans   &trans                         &trans   &kp F1   &kp F2    &kp F3    &kp F4    &trans
                                              &trans   &trans   &trans       &trans   &trans   &trans
            >;
        };

    };
};
